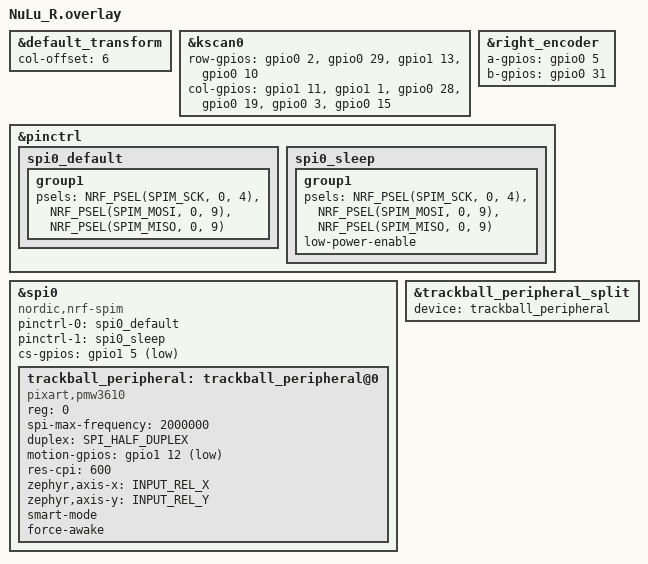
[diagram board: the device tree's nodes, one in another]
#include "NuLu.dtsi"
#include <zephyr/dt-bindings/input/input-event-codes.h>
#include <zephyr/dt-bindings/spi/spi.h>

&default_transform {
    col-offset = <6>;
};

&kscan0 {
    row-gpios
        = <&gpio0 2 (GPIO_ACTIVE_HIGH | GPIO_PULL_DOWN)>  /* Row0 */
        , <&gpio0 29 (GPIO_ACTIVE_HIGH | GPIO_PULL_DOWN)> /* Row1 */
        , <&gpio1 13 (GPIO_ACTIVE_HIGH | GPIO_PULL_DOWN)> /* Row2 */
        , <&gpio0 10 (GPIO_ACTIVE_HIGH | GPIO_PULL_DOWN)> /* Row3 */
        ;

    col-gpios
        = <&gpio1 11 GPIO_ACTIVE_HIGH> /* Col0 */
        , <&gpio1 1 GPIO_ACTIVE_HIGH>  /* Col1 */
        , <&gpio0 28 GPIO_ACTIVE_HIGH> /* Col2 */
        , <&gpio0 19 GPIO_ACTIVE_HIGH> /* Col3 */
        , <&gpio0 3 GPIO_ACTIVE_HIGH>  /* Col4 */
        , <&gpio0 15 GPIO_ACTIVE_HIGH> /* Col5 */
        ;
};

&right_encoder {
    a-gpios = <&gpio0 5 (GPIO_ACTIVE_HIGH | GPIO_PULL_UP)>;
    b-gpios = <&gpio0 31 (GPIO_ACTIVE_HIGH | GPIO_PULL_UP)>;
    status = "okay";
};

&pinctrl {
    spi0_default: spi0_default {
        group1 {
            psels = <NRF_PSEL(SPIM_SCK, 0, 4)>,
                <NRF_PSEL(SPIM_MOSI, 0, 9)>,
                <NRF_PSEL(SPIM_MISO, 0, 9)>;
        };
    };

    spi0_sleep: spi0_sleep {
        group1 {
            psels = <NRF_PSEL(SPIM_SCK, 0, 4)>,
                <NRF_PSEL(SPIM_MOSI, 0, 9)>,
                <NRF_PSEL(SPIM_MISO, 0, 9)>;
            low-power-enable;
        };
    };
};

&spi0 {
    status = "okay";
    compatible = "nordic,nrf-spim";
    pinctrl-0 = <&spi0_default>;
    pinctrl-1 = <&spi0_sleep>;
    pinctrl-names = "default", "sleep";
    cs-gpios = <&gpio1 5 GPIO_ACTIVE_LOW>;

    trackball_peripheral: trackball_peripheral@0 {
        status = "okay";
        compatible = "pixart,pmw3610";
        reg = <0>;
        spi-max-frequency = <2000000>;
        duplex = <SPI_HALF_DUPLEX>;
        motion-gpios = <&gpio1 12 (GPIO_ACTIVE_LOW | GPIO_PULL_UP)>;
        res-cpi = <600>;
        zephyr,axis-x = <INPUT_REL_X>;
        zephyr,axis-y = <INPUT_REL_Y>;
        smart-mode;
        force-awake;
    };
};

&trackball_peripheral_split {
    status = "okay";
    device = <&trackball_peripheral>;
};
